AUTOSAR XML (schema 4.0)
standard types defined: float32, float64, sint16, sint32, sint8, uint16, uint32, uint8, void, boolean
package /ImplDataTypes
  7 x impl type, all with category=TYPE_REFERENCE, type-emitter=RTE:
    IoPositionSensorReadingType: implementation-data-type=uint8
    IoWeightSensorReadingType: implementation-data-type=uint16
    MultuStateBtnType: implementation-data-type=uint8
    SeatModeBtnType: implementation-data-type=uint8
    SensorPositionType: implementation-data-type=MultuStateBtnType
    SensorWeightType: implementation-data-type=uint8
    StepMotorStepType: implementation-data-type=void
package /MappingSets
  data type mapping set MappingSet: mode-request-type-map{implementation-data-type=uint8, mode-group=SeatCtrlMode}
package /PortInterfaces/ClientServer
  8 x client server interface:
    CsIf_HeightMotor
      operation Opr_HeightMotorMove
        arg Step: type=StepMotorStepType, direction=IN
    CsIf_InclineMotor
      operation Opr_InclineMotorMove
        arg Step: type=StepMotorStepType, direction=IN
    CsIf_IoGetSensorPosition
      operation IOGet
        arg position: type=IoPositionSensorReadingType, direction=OUT
    CsIf_IoGetSensorWeight
      operation IOGet
        arg weight: type=IoWeightSensorReadingType, direction=OUT
    CsIf_IoSetMotor
      operation IOSetForward
      operation IOSetReverse
    CsIf_PositionSensor
      operation GetPosition
        arg position: type=SensorPositionType, direction=OUT
    CsIf_SlideMotor
      operation Opr_SlideMotorMove
        arg Step: type=StepMotorStepType, direction=IN
    CsIf_WeightSensor
      operation GetWeight
        arg weight: type=SensorWeightType, direction=OUT
package /PortInterfaces/ModeSwitch
  mode switch interface MsIf_SeatCtrlMode
    mode group SeatCtrlMode: type=SeatCtrlMode
  mode declaration group SeatCtrlMode: category=ALPHABETIC_ORDER, initial-mode=INIT, on-transition-value=255
    mode AUTO
    mode INIT
    mode MANUAL
package /PortInterfaces/SenderReceiver
  sender receiver interface SeatCtrlBtns
    data HeightBtnState: type=MultuStateBtnType
    data InclineBtnState: type=MultuStateBtnType
    data SlideBtnState: type=MultuStateBtnType
  sender receiver interface SeatCtrlData
    data Height: type=uint8
    data Incline: type=uint8
    data Slide: type=uint8
  sender receiver interface SrIf_SeatModeBtn
    data SeatModeBtn: type=SeatModeBtnType
package /SoftwareComponents
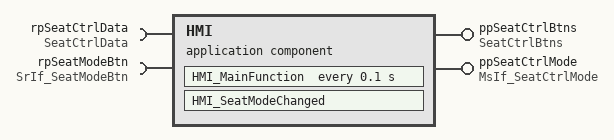
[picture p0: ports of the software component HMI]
  application sw component type HMI
    provide port ppSeatCtrlBtns: provided-interface=SeatCtrlBtns
    provide port ppSeatCtrlMode: provided-interface=MsIf_SeatCtrlMode
    require port rpSeatCtrlData: required-interface=SeatCtrlData
    require port rpSeatModeBtn: required-interface=SrIf_SeatModeBtn
    behavior Ibhv_HMI: data-type-mapping=MappingSet, handle-termination-and-restart=NO-SUPPORT
      data received event DRE_rpSeatModeBtn_SeatModeBtn: start-on-event=HMI_SeatModeChanged, data=rpSeatModeBtn.SeatModeBtn
      timing event TE_HMI_MainFunction_100ms: start-on-event=HMI_MainFunction, period=0.1
      runnable HMI_MainFunction
        data-receive-point-by-arguments:
          access DRP_rpSeatCtrlData_Height: accessed-variable=rpSeatCtrlData.Height
          access DRP_rpSeatCtrlData_Incline: accessed-variable=rpSeatCtrlData.Incline
          access DRP_rpSeatCtrlData_Slide: accessed-variable=rpSeatCtrlData.Slide
        data-send-points:
          access DSP_ppSeatCtrlBtns_HeightBtnState: accessed-variable=ppSeatCtrlBtns.HeightBtnState
          access DSP_ppSeatCtrlBtns_InclineBtnState: accessed-variable=ppSeatCtrlBtns.InclineBtnState
          access DSP_ppSeatCtrlBtns_SlideBtnState: accessed-variable=ppSeatCtrlBtns.SlideBtnState
      runnable HMI_SeatModeChanged
        data-receive-point-by-arguments:
          access DRP_rpSeatModeBtn_SeatModeBtn: accessed-variable=rpSeatModeBtn.SeatModeBtn
        mode switch point MSP_ppSeatCtrlMode_ppSeatCtrlMode: mode-group=ppSeatCtrlMode.SeatCtrlMode
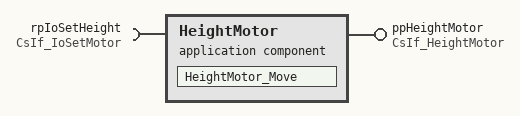
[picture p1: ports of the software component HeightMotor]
  application sw component type HeightMotor
    provide port ppHeightMotor: provided-interface=CsIf_HeightMotor
    require port rpIoSetHeight: required-interface=CsIf_IoSetMotor
    behavior Ibhv_HeightMotor: data-type-mapping=MappingSet, handle-termination-and-restart=NO-SUPPORT
      operation invoked event OIE_ppHeightMotor_Opr_HeightMotorMove: start-on-event=HeightMotor_Move, operation=ppHeightMotor.Opr_HeightMotorMove
      runnable HeightMotor_Move
        sync call SCP_rpIoSetHeight_IOSetForward: operation=rpIoSetHeight.IOSetForward, timeout=0.0
        sync call SCP_rpIoSetHeight_IOSetReverse: operation=rpIoSetHeight.IOSetReverse, timeout=0.0
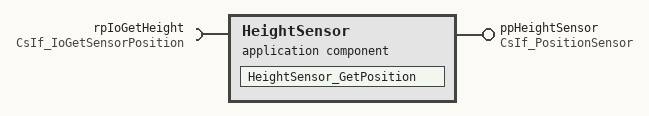
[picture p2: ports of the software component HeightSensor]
  application sw component type HeightSensor
    provide port ppHeightSensor: provided-interface=CsIf_PositionSensor
    require port rpIoGetHeight: required-interface=CsIf_IoGetSensorPosition
    behavior Ibhv_HeightSensor: data-type-mapping=MappingSet, handle-termination-and-restart=NO-SUPPORT
      operation invoked event OIE_ppHeightSensor_GetPosition: start-on-event=HeightSensor_GetPosition, operation=ppHeightSensor.GetPosition
      runnable HeightSensor_GetPosition
        sync call SCP_rpIoGetHeight_IOGet: operation=rpIoGetHeight.IOGet, timeout=0.0
  10 x swc implementation, all with programming-language=C, sw-version=1.0.0, vendor-id=255:
    Impl_HMI: behavior=Ibhv_HMI
      code-descriptors:
        code Code: artifact-descriptors=autosar-engineering-object={short-label=SWC.c, category=SWSRC}
      resource consumption ResourceConsumption
    Impl_HeightMotor: behavior=Ibhv_HeightMotor
      code-descriptors:
        code Code: artifact-descriptors=autosar-engineering-object={short-label=SWC.c, category=SWSRC}
      resource consumption ResourceConsumption
    Impl_HeightSensor: behavior=Ibhv_HeightSensor
      code-descriptors:
        code Code: artifact-descriptors=autosar-engineering-object={short-label=SWC.c, category=SWSRC}
      resource consumption ResourceConsumption
    Impl_InclineMotor: behavior=Ibhv_InclineMotor
      code-descriptors:
        code Code: artifact-descriptors=autosar-engineering-object={short-label=SWC.c, category=SWSRC}
      resource consumption ResourceConsumption
    Impl_InclineSensor: behavior=Ibhv_InclineSensor
      code-descriptors:
        code Code: artifact-descriptors=autosar-engineering-object={short-label=SWC.c, category=SWSRC}
      resource consumption ResourceConsumption
    Impl_IoHwAbs: behavior=Ibhv_IoHwAbs
      code-descriptors:
        code Code: artifact-descriptors=autosar-engineering-object={short-label=SWC.c, category=SWSRC}
      resource consumption ResourceConsumption
    Impl_SeatManager: behavior=Ibhv_SeatManager
      code-descriptors:
        code Code: artifact-descriptors=autosar-engineering-object={short-label=SWC.c, category=SWSRC}
      resource consumption ResourceConsumption
    Impl_SlideMotor: behavior=Ibhv_SlideMotor
      code-descriptors:
        code Code: artifact-descriptors=autosar-engineering-object={short-label=SWC.c, category=SWSRC}
      resource consumption ResourceConsumption
    Impl_SlideSensor: behavior=Ibhv_SlideSensor
      code-descriptors:
        code Code: artifact-descriptors=autosar-engineering-object={short-label=SWC.c, category=SWSRC}
      resource consumption ResourceConsumption
    Impl_WeightSensor: behavior=Ibhv_WeightSensor
      code-descriptors:
        code Code: artifact-descriptors=autosar-engineering-object={short-label=SWC.c, category=SWSRC}
      resource consumption ResourceConsumption
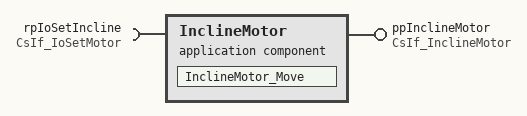
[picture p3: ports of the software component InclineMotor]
  application sw component type InclineMotor
    provide port ppInclineMotor: provided-interface=CsIf_InclineMotor
    require port rpIoSetIncline: required-interface=CsIf_IoSetMotor
    behavior Ibhv_InclineMotor: data-type-mapping=MappingSet, handle-termination-and-restart=NO-SUPPORT
      operation invoked event OIE_ppInclineMotor_Opr_InclineMotorMove: start-on-event=InclineMotor_Move, operation=ppInclineMotor.Opr_InclineMotorMove
      runnable InclineMotor_Move
        sync call SCP_rpIoSetIncline_IOSetForward: operation=rpIoSetIncline.IOSetForward, timeout=0.0
        sync call SCP_rpIoSetIncline_IOSetReverse: operation=rpIoSetIncline.IOSetReverse, timeout=0.0
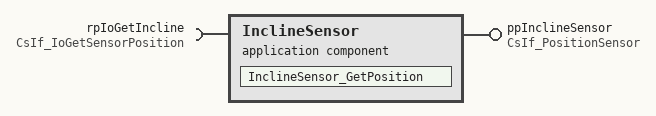
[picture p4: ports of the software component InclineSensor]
  application sw component type InclineSensor
    provide port ppInclineSensor: provided-interface=CsIf_PositionSensor
    require port rpIoGetIncline: required-interface=CsIf_IoGetSensorPosition
    behavior Ibhv_InclineSensor: data-type-mapping=MappingSet, handle-termination-and-restart=NO-SUPPORT
      operation invoked event OIE_ppInclineSensor_GetPosition: start-on-event=InclineSensor_GetPosition, operation=ppInclineSensor.GetPosition
      runnable InclineSensor_GetPosition
        sync call SCP_rpIoGetIncline_IOGet: operation=rpIoGetIncline.IOGet, timeout=0.0
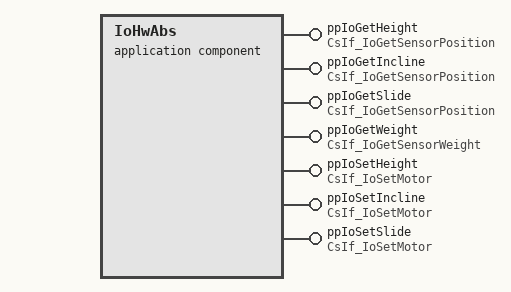
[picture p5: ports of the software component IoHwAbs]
  application sw component type IoHwAbs
    7 x provide port:
      ppIoGetHeight: provided-interface=CsIf_IoGetSensorPosition
      ppIoGetIncline: provided-interface=CsIf_IoGetSensorPosition
      ppIoGetSlide: provided-interface=CsIf_IoGetSensorPosition
      ppIoGetWeight: provided-interface=CsIf_IoGetSensorWeight
      ppIoSetHeight: provided-interface=CsIf_IoSetMotor
      ppIoSetIncline: provided-interface=CsIf_IoSetMotor
      ppIoSetSlide: provided-interface=CsIf_IoSetMotor
    behavior Ibhv_IoHwAbs: data-type-mapping=MappingSet, handle-termination-and-restart=NO-SUPPORT
      10 x operation invoked event:
        OIE_ppIoGetHeight_IOGet: start-on-event=IoHwAbs_EcuGet_Height, operation=ppIoGetHeight.IOGet
        OIE_ppIoGetIncline_IOGet: start-on-event=IoHwAbs_EcuGet_Incline, operation=ppIoGetIncline.IOGet
        OIE_ppIoGetSlide_IOGet: start-on-event=IoHwAbs_EcuGet_Slide, operation=ppIoGetSlide.IOGet
        OIE_ppIoGetWeight_IOGet: start-on-event=IoHwAbs_EcuGet_Weight, operation=ppIoGetWeight.IOGet
        OIE_ppIoSetHeight_IOSetForward: start-on-event=IoHwAbs_EcuSetForward_Height, operation=ppIoSetHeight.IOSetForward
        OIE_ppIoSetHeight_IOSetReverse: start-on-event=IoHwAbs_EcuSetReverse_Height, operation=ppIoSetHeight.IOSetReverse
        OIE_ppIoSetIncline_IOSetForward: start-on-event=IoHwAbs_EcuSetForward_Incline, operation=ppIoSetIncline.IOSetForward
        OIE_ppIoSetIncline_IOSetReverse: start-on-event=IoHwAbs_EcuSetReverse_Incline, operation=ppIoSetIncline.IOSetReverse
        OIE_ppIoSetSlide_IOSetForward: start-on-event=IoHwAbs_EcuSetForward_Slide, operation=ppIoSetSlide.IOSetForward
        OIE_ppIoSetSlide_IOSetReverse: start-on-event=IoHwAbs_EcuSetReverse_Slide, operation=ppIoSetSlide.IOSetReverse
      10 x runnable:
        IoHwAbs_EcuGet_Height
        IoHwAbs_EcuGet_Incline
        IoHwAbs_EcuGet_Slide
        IoHwAbs_EcuGet_Weight
        IoHwAbs_EcuSetForward_Height
        IoHwAbs_EcuSetForward_Incline
        IoHwAbs_EcuSetForward_Slide
        IoHwAbs_EcuSetReverse_Height
        IoHwAbs_EcuSetReverse_Incline
        IoHwAbs_EcuSetReverse_Slide
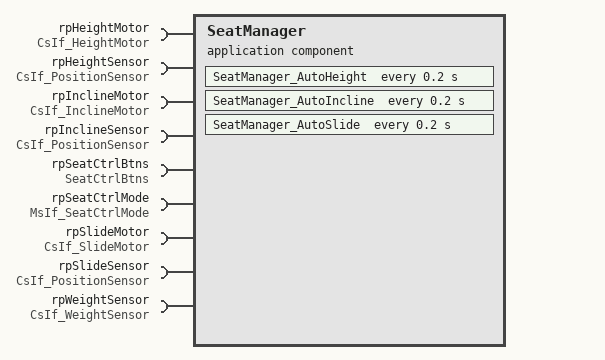
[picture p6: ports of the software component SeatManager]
  application sw component type SeatManager
    9 x require port:
      rpHeightMotor: required-interface=CsIf_HeightMotor
      rpHeightSensor: required-interface=CsIf_PositionSensor
      rpInclineMotor: required-interface=CsIf_InclineMotor
      rpInclineSensor: required-interface=CsIf_PositionSensor
      rpSeatCtrlBtns: required-interface=SeatCtrlBtns
      rpSeatCtrlMode: required-interface=MsIf_SeatCtrlMode
      rpSlideMotor: required-interface=CsIf_SlideMotor
      rpSlideSensor: required-interface=CsIf_PositionSensor
      rpWeightSensor: required-interface=CsIf_WeightSensor
    behavior Ibhv_SeatManager: data-type-mapping=MappingSet, handle-termination-and-restart=NO-SUPPORT
      data received event DRE_rpSeatCtrlBtns_HeightBtnState: start-on-event=SeatManager_SetHeight, data=rpSeatCtrlBtns.HeightBtnState
      data received event DRE_rpSeatCtrlBtns_InclineBtnState: start-on-event=SeatManager_SetInclice, data=rpSeatCtrlBtns.InclineBtnState
      data received event DRE_rpSeatCtrlBtns_SlideBtnState: start-on-event=SeatManager_SetSlide, data=rpSeatCtrlBtns.SlideBtnState
      timing event TE_SeatManager_AutoHeight_200ms: start-on-event=SeatManager_AutoHeight, period=0.2
      timing event TE_SeatManager_AutoIncline_200ms: start-on-event=SeatManager_AutoIncline, period=0.2
      timing event TE_SeatManager_AutoSlide_200ms: start-on-event=SeatManager_AutoSlide, period=0.2
      6 x runnable:
        SeatManager_AutoHeight
          sync call SCP_rpHeightMotor_Opr_HeightMotorMove: operation=rpHeightMotor.Opr_HeightMotorMove, timeout=0.0
          sync call SCP_rpHeightSensor_GetPosition: operation=rpHeightSensor.GetPosition, timeout=0.0
          sync call SCP_rpWeightSensor_GetWeight: operation=rpWeightSensor.GetWeight, timeout=0.0
        SeatManager_AutoIncline
          sync call SCP_rpInclineMotor_Opr_InclineMotorMove: operation=rpInclineMotor.Opr_InclineMotorMove, timeout=0.0
          sync call SCP_rpInclineSensor_GetPosition: operation=rpInclineSensor.GetPosition, timeout=0.0
          sync call SCP_rpWeightSensor_GetWeight: operation=rpWeightSensor.GetWeight, timeout=0.0
        SeatManager_AutoSlide
          sync call SCP_rpSlideMotor_Opr_SlideMotorMove: operation=rpSlideMotor.Opr_SlideMotorMove, timeout=0.0
          sync call SCP_rpSlideSensor_GetPosition: operation=rpSlideSensor.GetPosition, timeout=0.0
          sync call SCP_rpWeightSensor_GetWeight: operation=rpWeightSensor.GetWeight, timeout=0.0
        SeatManager_SetHeight
          data-receive-point-by-arguments:
            access DRP_rpSeatCtrlBtns_HeightBtnState: accessed-variable=rpSeatCtrlBtns.HeightBtnState
          sync call SCP_rpHeightMotor_Opr_HeightMotorMove: operation=rpHeightMotor.Opr_HeightMotorMove, timeout=0.0
        SeatManager_SetInclice
          data-receive-point-by-arguments:
            access DRP_rpSeatCtrlBtns_InclineBtnState: accessed-variable=rpSeatCtrlBtns.InclineBtnState
          sync call SCP_rpInclineMotor_Opr_InclineMotorMove: operation=rpInclineMotor.Opr_InclineMotorMove, timeout=0.0
        SeatManager_SetSlide
          data-receive-point-by-arguments:
            access DRP_rpSeatCtrlBtns_SlideBtnState: accessed-variable=rpSeatCtrlBtns.SlideBtnState
          sync call SCP_rpSlideMotor_Opr_SlideMotorMove: operation=rpSlideMotor.Opr_SlideMotorMove, timeout=0.0
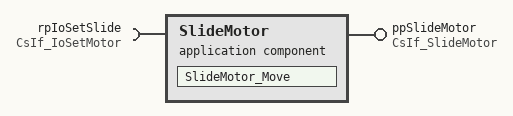
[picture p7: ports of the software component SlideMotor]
  application sw component type SlideMotor
    provide port ppSlideMotor: provided-interface=CsIf_SlideMotor
    require port rpIoSetSlide: required-interface=CsIf_IoSetMotor
    behavior Ibhv_SlideMotor: data-type-mapping=MappingSet, handle-termination-and-restart=NO-SUPPORT
      operation invoked event OIE_ppSlideMotor_Opr_SlideMotorMove: start-on-event=SlideMotor_Move, operation=ppSlideMotor.Opr_SlideMotorMove
      runnable SlideMotor_Move
        sync call SCP_rpIoSetSlide_IOSetForward: operation=rpIoSetSlide.IOSetForward, timeout=0.0
        sync call SCP_rpIoSetSlide_IOSetReverse: operation=rpIoSetSlide.IOSetReverse, timeout=0.0
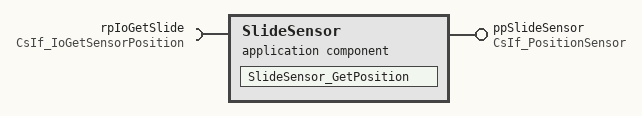
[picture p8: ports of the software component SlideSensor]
  application sw component type SlideSensor
    provide port ppSlideSensor: provided-interface=CsIf_PositionSensor
    require port rpIoGetSlide: required-interface=CsIf_IoGetSensorPosition
    behavior Ibhv_SlideSensor: data-type-mapping=MappingSet, handle-termination-and-restart=NO-SUPPORT
      operation invoked event OIE_ppSlideSensor_GetPosition: start-on-event=SlideSensor_GetPosition, operation=ppSlideSensor.GetPosition
      runnable SlideSensor_GetPosition
        sync call SCP_rpIoGetSlide_IOGet: operation=rpIoGetSlide.IOGet, timeout=0.0
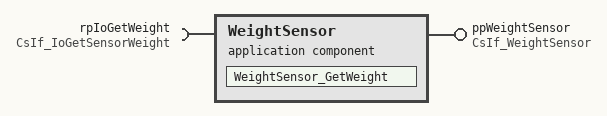
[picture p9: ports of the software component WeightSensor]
  application sw component type WeightSensor
    provide port ppWeightSensor: provided-interface=CsIf_WeightSensor
    require port rpIoGetWeight: required-interface=CsIf_IoGetSensorWeight
    behavior Ibhv_WeightSensor: data-type-mapping=MappingSet, handle-termination-and-restart=NO-SUPPORT
      operation invoked event OIE_ppWeightSensor_GetWeight: start-on-event=WeightSensor_GetWeight, operation=ppWeightSensor.GetWeight
      runnable WeightSensor_GetWeight
        sync call SCP_rpIoGetWeight_IOGet: operation=rpIoGetWeight.IOGet, timeout=0.0
package /Compositions
  composition sw component type TestAppComposition
    10 x component:
      HMI: type=HMI
      HeightMotor: type=HeightMotor
      HeightSensor: type=HeightSensor
      InclineMotor: type=InclineMotor
      InclineSensor: type=InclineSensor
      IoHwAbs: type=IoHwAbs
      SeatManager: type=SeatManager
      SlideMotor: type=SlideMotor
      SlideSensor: type=SlideSensor
      WeightSensor: type=WeightSensor
    connect HMI.ppSeatCtrlBtns -> SeatManager.rpSeatCtrlBtns
    connect HMI.ppSeatCtrlMode -> SeatManager.rpSeatCtrlMode
    connect HeightMotor.ppHeightMotor -> SeatManager.rpHeightMotor
    connect HeightSensor.ppHeightSensor -> SeatManager.rpHeightSensor
    connect InclineMotor.ppInclineMotor -> SeatManager.rpInclineMotor
    connect InclineSensor.ppInclineSensor -> SeatManager.rpInclineSensor
    connect IoHwAbs.ppIoGetHeight -> HeightSensor.rpIoGetHeight
    connect IoHwAbs.ppIoGetIncline -> InclineSensor.rpIoGetIncline
    connect IoHwAbs.ppIoGetSlide -> SlideSensor.rpIoGetSlide
    connect IoHwAbs.ppIoGetWeight -> WeightSensor.rpIoGetWeight
    connect IoHwAbs.ppIoSetHeight -> HeightMotor.rpIoSetHeight
    connect IoHwAbs.ppIoSetIncline -> InclineMotor.rpIoSetIncline
    connect IoHwAbs.ppIoSetSlide -> SlideMotor.rpIoSetSlide
    connect SlideMotor.ppSlideMotor -> SeatManager.rpSlideMotor
    connect SlideSensor.ppSlideSensor -> SeatManager.rpSlideSensor
    connect WeightSensor.ppWeightSensor -> SeatManager.rpWeightSensor
